# nrf54h20_engb_radiocore register map
Vendor: Nordic Semiconductor; Series: nRF54h; File version: 1
CPU: CM33 r0p4, little endian, MPU, FPU, 3 interrupt priority bits, 480 interrupts, 8 SAU regions
Registers are 32-bit, read-write, reset 0x0 unless marked. A register's access mark holds for its fields unless they carry their own. Offsets are from the block's base; [hi:lo] are bit positions; lines under a group give offsets from that group; {n}, {i} and the like mark numbered series; 'fields as' and 'values as' point back to an identical list.

## IPCT_NS — IPCT APB registers 0
Base 0x43024000
Same registers: IPCT_S 0x53024000
{0x0+4i} TASKS_SEND[{i}] (i=0..7) wo — Description collection: Trigger event on IPCT source channel n if there are no active signals present on that channel
  [0] TASKS_SEND — Trigger event on IPCT source channel n if there are no active signals present on that channel
    1=Trigger task
{0x40+4i} TASKS_FLUSH[{i}] (i=0..7) wo — Description collection: Flush IPCT sink channel n. Any pending IPCT signal on that channel will re-trigger the RECEIVE[n] event. The flush can happen automatically by configuring the SHORTS register accordingly.
  [0] TASKS_FLUSH — Flush IPCT sink channel n. Any pending IPCT signal on that channel will re-trigger the RECEIVE[n] event. The flush can happen automatically by configuring the SHORTS register accordingly.
    1=Trigger task
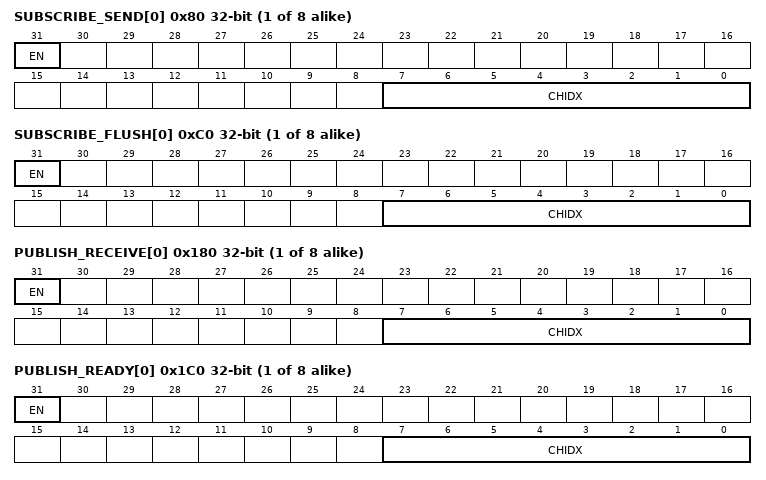
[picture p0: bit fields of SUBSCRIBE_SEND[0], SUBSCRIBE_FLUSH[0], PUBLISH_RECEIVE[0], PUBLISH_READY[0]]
{0x80+4i} SUBSCRIBE_SEND[{i}] (i=0..7) — Description collection: Subscribe configuration for task SEND[n]
  [31] EN
    0=Disabled (Disable subscription); 1=Enabled (Enable subscription)
  [7:0] CHIDX — DPPI channel that task SEND[n] will subscribe to
{0xC0+4i} SUBSCRIBE_FLUSH[{i}] (i=0..7) — Description collection: Subscribe configuration for task FLUSH[n]
  [31] EN
    values as SUBSCRIBE_SEND[0].EN
  [7:0] CHIDX — DPPI channel that task FLUSH[n] will subscribe to
{0x100+4i} EVENTS_RECEIVE[{i}] (i=0..7) — Description collection: Event received on IPCT sink channel n
  [0] EVENTS_RECEIVE — Event received on IPCT sink channel n
    0=NotGenerated (Event not generated); 1=Generated (Event generated)
{0x140+4i} EVENTS_READY[{i}] (i=0..7) — Description collection: Event received when hardware handshake of SEND task for IPCT source channel n is complete and a new signal can be triggered on that channel.
  [0] EVENTS_READY — Event received when hardware handshake of SEND task for IPCT source channel n is complete and a new signal can be triggered on that channel.
    values as EVENTS_RECEIVE[0].EVENTS_RECEIVE
{0x180+4i} PUBLISH_RECEIVE[{i}] (i=0..7) — Description collection: Publish configuration for event RECEIVE[n]
  [31] EN
    0=Disabled (Disable publishing); 1=Enabled (Enable publishing)
  [7:0] CHIDX — DPPI channel that event RECEIVE[n] will publish to
{0x1C0+4i} PUBLISH_READY[{i}] (i=0..7) — Description collection: Publish configuration for event READY[n]
  [31] EN
    values as PUBLISH_RECEIVE[0].EN
  [7:0] CHIDX — DPPI channel that event READY[n] will publish to
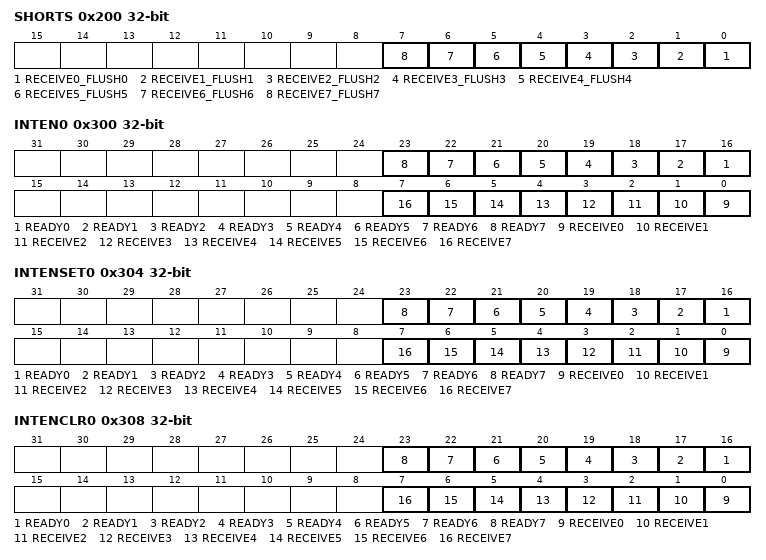
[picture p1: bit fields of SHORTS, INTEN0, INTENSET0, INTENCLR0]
0x200 SHORTS — Shortcuts between local events and tasks
  [all] fields
    0=Disabled (Disable shortcut); 1=Enabled (Enable shortcut)
  [n] RECEIVE{n}_FLUSH{n} (n=0..7) — Shortcut between event RECEIVE[{n}] and task FLUSH[{n}]
0x300 INTEN0 — Enable or disable interrupt
  [all] fields
    0=Disabled; 1=Enabled
  [n+16] READY{n} (n=0..7) — Enable or disable interrupt for event READY[{n}]
  [n] RECEIVE{n} (n=0..7) — Enable or disable interrupt for event RECEIVE[{n}]
0x304 INTENSET0 — Enable interrupt
  [all] fields
    on read: 0=Disabled (Read: Disabled); 1=Enabled (Read: Enabled) | on write: 1=Set (Enable)
  [n+16] READY{n} (n=0..7) — Write '1' to enable interrupt for event READY[{n}]
  [n] RECEIVE{n} (n=0..7) — Write '1' to enable interrupt for event RECEIVE[{n}]
0x308 INTENCLR0 — Disable interrupt
  [all] fields
    on read: 0=Disabled (Read: Disabled); 1=Enabled (Read: Enabled) | on write: 1=Clear (Disable)
  [n+16] READY{n} (n=0..7) — Write '1' to disable interrupt for event READY[{n}]
  [n] RECEIVE{n} (n=0..7) — Write '1' to disable interrupt for event RECEIVE[{n}]
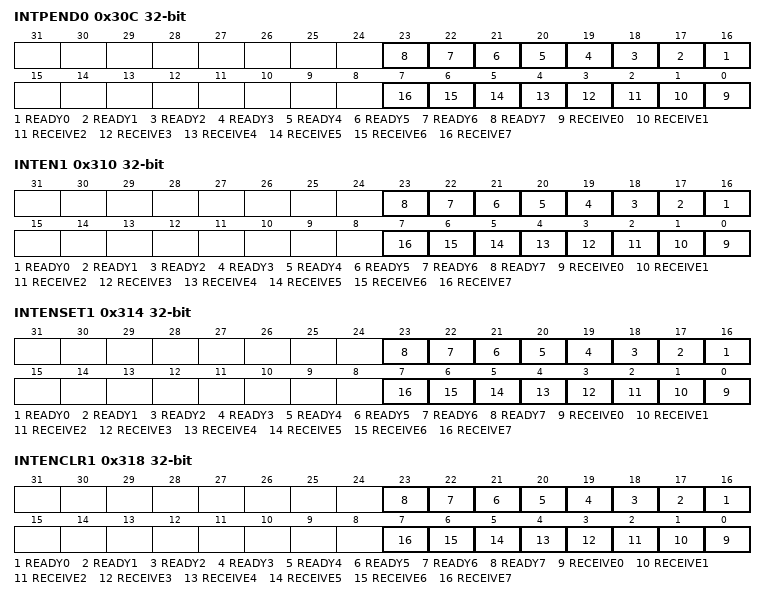
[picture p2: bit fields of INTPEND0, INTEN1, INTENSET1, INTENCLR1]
0x30C INTPEND0 ro — Pending interrupts
  [all] fields
    on read: 0=NotPending (Read: Not pending); 1=Pending (Read: Pending)
  [n+16] READY{n} (n=0..7) — Read pending status of interrupt for event READY[{n}]
  [n] RECEIVE{n} (n=0..7) — Read pending status of interrupt for event RECEIVE[{n}]
0x310 INTEN1 — Enable or disable interrupt
  fields as INTEN0
0x314 INTENSET1 — Enable interrupt
  fields as INTENSET0
0x318 INTENCLR1 — Disable interrupt
  fields as INTENCLR0
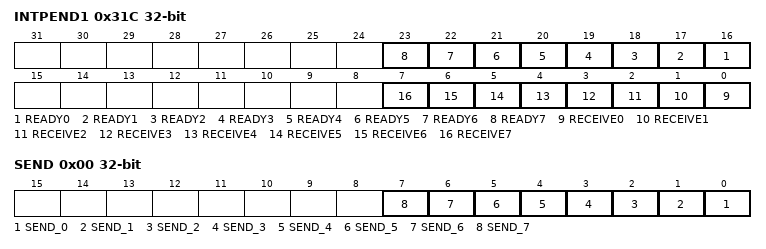
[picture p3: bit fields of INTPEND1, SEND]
0x31C INTPEND1 ro — Pending interrupts
  fields as INTPEND0
0x400 OVERFLOW group — Unspecified
  0x00 SEND — Overflow status for SEND tasks Write 0 to clear
    [all] fields
      1=Overflow (Task overflow has happened); 0=NoOverflow (Task overflow has not happened)
    [n] SEND_{n} (n=0..7) — Overflow status for SEND[{n}] task

## GLOBAL_IPCT120_NS — IPCT APB registers 0
Base 0x4F8D1000
Same registers: GLOBAL_IPCT130_NS 0x4F921000, GLOBAL_IPCT120_S 0x5F8D1000, GLOBAL_IPCT130_S 0x5F921000
Registers as IPCT_NS, without INTEN0, INTENSET0, INTENCLR0, INTPEND0, INTEN1, INTENSET1, INTENCLR1, INTPEND1; these are added or differ:
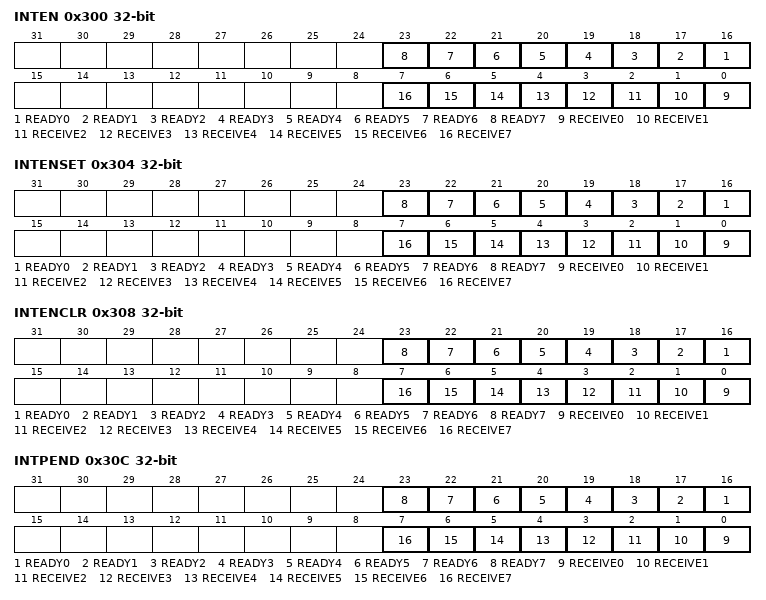
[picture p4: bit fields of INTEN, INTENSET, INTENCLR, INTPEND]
0x300 INTEN — Enable or disable interrupt
  [all] fields
    0=Disabled; 1=Enabled
  [n+16] READY{n} (n=0..7) — Enable or disable interrupt for event READY[{n}]
  [n] RECEIVE{n} (n=0..7) — Enable or disable interrupt for event RECEIVE[{n}]
0x304 INTENSET — Enable interrupt
  fields as IPCT_NS.INTENSET0
0x308 INTENCLR — Disable interrupt
  fields as IPCT_NS.INTENCLR0
0x30C INTPEND ro — Pending interrupts
  fields as IPCT_NS.INTPEND0
